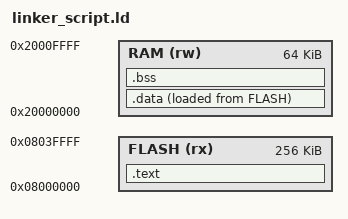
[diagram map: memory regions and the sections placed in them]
MEMORY
{
    FLASH (rx) : ORIGIN = 0x08000000, LENGTH = 256K
    RAM (rw) : ORIGIN = 0x20000000, LENGTH = 64K
}

SECTIONS
{
    .text : { *(.text*) } > FLASH
    .data : { *(.data*) } > RAM AT > FLASH
    .bss : { *(.bss*) } > RAM
}
